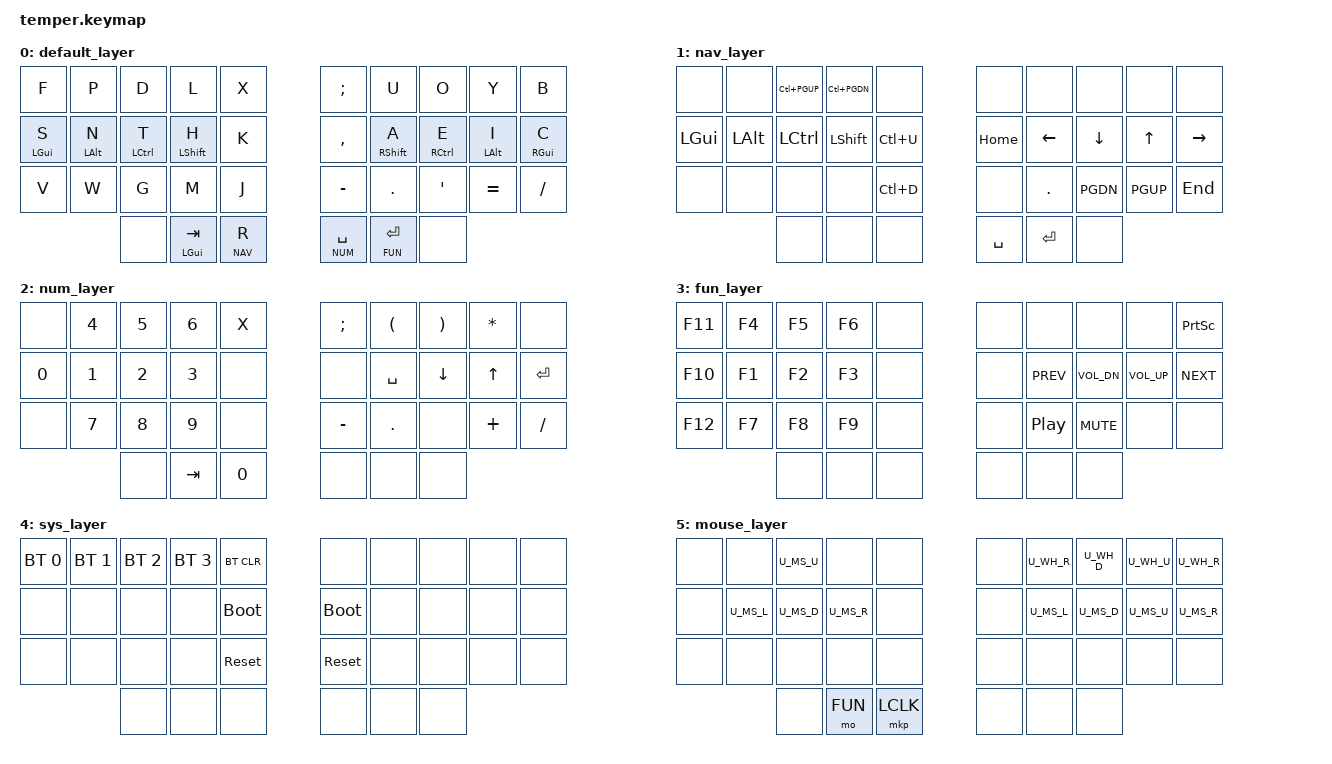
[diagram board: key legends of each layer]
#include "helper.h"
#include "keypos_36.h"
#include <behaviors.dtsi>
#include <dt-bindings/zmk/bt.h>
#include <dt-bindings/zmk/keys.h>

#define DEF 0
#define NAV 1
#define NUM 2
#define FUN 3
#define SYS 4
#define MOUSE 5

#define XXX &none
#define ___ &trans

/* Global defaults */
#define QUICK_TAP_MS 150

&lt {
    flavor = "balanced";
    tapping-term-ms = <200>;
    quick-tap-ms = <QUICK_TAP_MS>;
};

&mt {
    flavor = "balanced";
    tapping-term-ms = <200>;
    quick-tap-ms = <QUICK_TAP_MS>;
};

MAKE_HRM(hml, &kp, &kp, KEYS_R THUMBS) // Left-hand HRMs.
MAKE_HRM(hmr, &kp, &kp, KEYS_L THUMBS) // Right-hand HRMs.

#include "combos.dtsi"
#include "mouse.dtsi"

/ {
    keymap {
        compatible = "zmk,keymap";
        default_layer {
            bindings = <
        // ╭─────────────┬─────────────┬─────────────┬─────────────┬─────────────╮   ╭─────────────┬─────────────┬─────────────┬─────────────┬─────────────╮
                &kp F         &kp P         &kp D         &kp L         &kp X           &kp SEMI        &kp U         &kp O         &kp Y         &kp B
        // ├─────────────┼─────────────┼─────────────┼─────────────┼─────────────┤   ├─────────────┼─────────────┼─────────────┼─────────────┼─────────────┤
             &hml LGUI S   &hml LALT N   &hml LCTRL T  &hml LSHIFT H    &kp K           &kp COMMA  &hmr RSHIFT A   &hmr RCTRL E  &hmr LALT I   &hmr RGUI C
        // ├─────────────┼─────────────┼─────────────┼─────────────┼─────────────┤   ├─────────────┼─────────────┼─────────────┼─────────────┼─────────────┤
                &kp V         &kp W         &kp G         &kp M         &kp J           &kp MINUS      &kp DOT      &kp APOS     &kp EQUAL     &kp SLASH
        // ╰─────────────┴─────────────┼─────────────┼─────────────┼─────────────┤   ├─────────────┼─────────────┼─────────────┼─────────────┴─────────────╯
                                             XXX      &mt LGUI TAB   &lt NAV R        &lt NUM SPACE  &lt FUN RET       XXX
        //                             ╰─────────────┴─────────────┴─────────────╯   ╰─────────────┴─────────────┴─────────────╯
            >;
        };

        nav_layer {
            bindings = <
        // ╭─────────────┬─────────────┬─────────────┬─────────────┬─────────────╮   ╭─────────────┬─────────────┬─────────────┬─────────────┬─────────────╮
                 XXX           XXX      &kp LC(PGUP)  &kp LC(PGDN)       XXX               XXX           XXX           XXX           XXX           XXX
        // ├─────────────┼─────────────┼─────────────┼─────────────┼─────────────┤   ├─────────────┼─────────────┼─────────────┼─────────────┼─────────────┤
              &kp LGUI      &kp LALT      &kp LCTRL    &kp LSHIFT    &kp LC(U)          &kp HOME      &kp LEFT      &kp DOWN      &kp UP       &kp RIGHT
        // ├─────────────┼─────────────┼─────────────┼─────────────┼─────────────┤   ├─────────────┼─────────────┼─────────────┼─────────────┼─────────────┤
                 XXX           XXX           XXX           XXX       &kp LC(D)             XXX         &kp DOT      &kp PGDN      &kp PGUP      &kp END
        // ╰─────────────┴─────────────┼─────────────┼─────────────┼─────────────┤   ├─────────────┼─────────────┼─────────────┼─────────────┴─────────────╯
                                             XXX           XXX           XXX            &kp SPACE      &kp RET         XXX
        //                             ╰─────────────┴─────────────┴─────────────╯   ╰─────────────┴─────────────┴─────────────╯
            >;
        };

        num_layer {
            bindings = <
        // ╭─────────────┬─────────────┬─────────────┬─────────────┬─────────────╮   ╭─────────────┬─────────────┬─────────────┬─────────────┬─────────────╮
                 XXX         &kp N4        &kp N5        &kp N6         &kp X           &kp SEMI     &kp LPAR      &kp RPAR       &kp STAR         XXX
        // ├─────────────┼─────────────┼─────────────┼─────────────┼─────────────┤   ├─────────────┼─────────────┼─────────────┼─────────────┼─────────────┤
               &kp N0        &kp N1        &kp N2        &kp N3          XXX               XXX       &kp SPACE     &kp DOWN       &kp UP        &kp RET
        // ├─────────────┼─────────────┼─────────────┼─────────────┼─────────────┤   ├─────────────┼─────────────┼─────────────┼─────────────┼─────────────┤
                 XXX         &kp N7        &kp N8        &kp N9          XXX            &kp MINUS     &kp DOT          XXX        &kp PLUS      &kp SLASH
        // ╰─────────────┴─────────────┼─────────────┼─────────────┼─────────────┤   ├─────────────┼─────────────┼─────────────┼─────────────┴─────────────╯
                                             XXX         &kp TAB       &kp N0               XXX           XXX           XXX
        //                             ╰─────────────┴─────────────┴─────────────╯   ╰─────────────┴─────────────┴─────────────╯
            >;
        };

        fun_layer {
            bindings = <
        // ╭─────────────┬─────────────┬─────────────┬─────────────┬─────────────╮   ╭─────────────┬─────────────┬─────────────┬─────────────┬─────────────╮
               &kp F11       &kp F4        &kp F5        &kp F6          XXX               XXX           XXX           XXX           XXX       &kp PSCRN
        // ├─────────────┼─────────────┼─────────────┼─────────────┼─────────────┤   ├─────────────┼─────────────┼─────────────┼─────────────┼─────────────┤
               &kp F10       &kp F1        &kp F2        &kp F3          XXX               XXX      &kp C_PREV  &kp C_VOL_DN   &kp C_VOL_UP    &kp C_NEXT
        // ├─────────────┼─────────────┼─────────────┼─────────────┼─────────────┤   ├─────────────┼─────────────┼─────────────┼─────────────┼─────────────┤
               &kp F12       &kp F7        &kp F8        &kp F9          XXX               XXX       &kp C_PP      &kp C_MUTE        XXX          XXX
        // ╰─────────────┴─────────────┼─────────────┼─────────────┼─────────────┤   ├─────────────┼─────────────┼─────────────┼─────────────┴─────────────╯
                                             XXX           XXX           XXX               XXX           XXX           XXX
        //                             ╰─────────────┴─────────────┴─────────────╯   ╰─────────────┴─────────────┴─────────────╯
            >;
        };

        sys_layer {
            bindings = <
        // ╭─────────────┬─────────────┬─────────────┬─────────────┬─────────────╮   ╭─────────────┬─────────────┬─────────────┬─────────────┬─────────────╮
            &bt BT_SEL 0  &bt BT_SEL 1  &bt BT_SEL 2  &bt BT_SEL 3   &bt BT_CLR            XXX           XXX           XXX           XXX           XXX
        // ├─────────────┼─────────────┼─────────────┼─────────────┼─────────────┤   ├─────────────┼─────────────┼─────────────┼─────────────┼─────────────┤
                 XXX           XXX           XXX           XXX       &bootloader       &bootloader       XXX           XXX           XXX           XXX
        // ├─────────────┼─────────────┼─────────────┼─────────────┼─────────────┤   ├─────────────┼─────────────┼─────────────┼─────────────┼─────────────┤
                 XXX           XXX           XXX           XXX       &sys_reset        &sys_reset        XXX           XXX           XXX           XXX
        // ╰─────────────┴─────────────┼─────────────┼─────────────┼─────────────┤   ├─────────────┼─────────────┼─────────────┼─────────────┴─────────────╯
                                             XXX           XXX           XXX               XXX           XXX           XXX
        //                             ╰─────────────┴─────────────┴─────────────╯   ╰─────────────┴─────────────┴─────────────╯
            >;
        };

        mouse_layer {
            bindings = <
                //╭─────────────┬─────────────┬─────────────┬─────────────┬─────────────╮ ╭─────────────┬─────────────┬─────────────┬─────────────┬─────────────╮
                        XXX           XXX          U_MS_U           XXX         XXX             XXX         U_WH_R        U_WH_D        U_WH_U        U_WH_R
                //├─────────────┼─────────────┼─────────────┼─────────────┼─────────────┤ ├─────────────┼─────────────┼─────────────┼─────────────┼─────────────┤
                        XXX           U_MS_L       U_MS_D        U_MS_R         XXX             XXX         U_MS_L        U_MS_D        U_MS_U        U_MS_R
                //├─────────────┼─────────────┼─────────────┼─────────────┼─────────────┤ ├─────────────┼─────────────┼─────────────┼─────────────┼─────────────┤
                        XXX           XXX           XXX           XXX           XXX             XXX          XXX           XXX          XXX           XXX
                //╰─────────────┼─────────────┴─────────────┼─────────────┼─────────────┤ ├─────────────┼─────────────┼─────────────┴───────────────────────────╯
                                                    XXX        &mo FUN      &mkp LCLK           XXX          XXX           XXX
                //                            ╰─────────────┴─────────────┴─────────────╯ ╰─────────────┴─────────────┴─────────────╯
            >;
        };
    };
};

// vim: filetype=c
// vim: syntax=off
